VERSION ""

NS_ :

BS_:

BU_:
VAL_TABLE_ bool 1 "true" 0 "false" ;

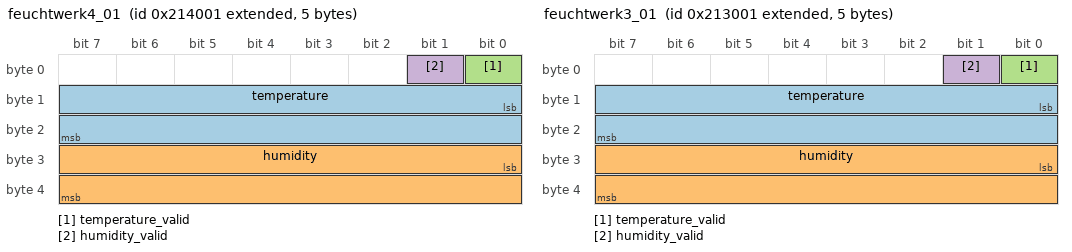
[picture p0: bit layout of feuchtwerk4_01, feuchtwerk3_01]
BO_ 2149662721 feuchtwerk4_01: 5 Vector__XXX
 SG_ temperature : 8|16@1+ (0.0025177,-40) [-40|125] "°C" Vector__XXX
 SG_ humidity : 24|16@1+ (0.00152590219,0) [0|100] "%" Vector__XXX
 SG_ temperature_valid : 0|1@1+ (1,0) [0|1] "" Vector__XXX
 SG_ humidity_valid : 1|1@1+ (1,0) [0|1] "" Vector__XXX

BO_ 2149658625 feuchtwerk3_01: 5 Vector__XXX
 SG_ temperature : 8|16@1+ (0.0025177,-40) [-40|125] "°C" Vector__XXX
 SG_ humidity : 24|16@1+ (0.00152590219,0) [0|100] "%" Vector__XXX
 SG_ temperature_valid : 0|1@1+ (1,0) [0|1] "" Vector__XXX
 SG_ humidity_valid : 1|1@1+ (1,0) [0|1] "" Vector__XXX

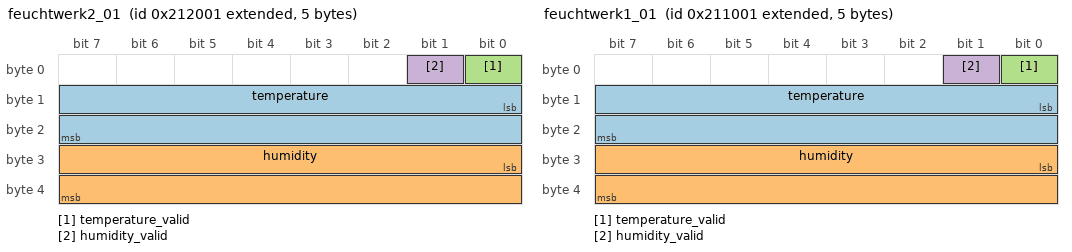
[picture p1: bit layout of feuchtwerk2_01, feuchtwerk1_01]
BO_ 2149654529 feuchtwerk2_01: 5 Vector__XXX
 SG_ temperature : 8|16@1+ (0.0025177,-40) [-40|125] "°C" Vector__XXX
 SG_ humidity : 24|16@1+ (0.00152590219,0) [0|100] "%" Vector__XXX
 SG_ temperature_valid : 0|1@1+ (1,0) [0|1] "" Vector__XXX
 SG_ humidity_valid : 1|1@1+ (1,0) [0|1] "" Vector__XXX

BO_ 2149650433 feuchtwerk1_01: 5 Vector__XXX
 SG_ temperature : 8|16@1+ (0.0025177,-40) [-40|125] "°C" Vector__XXX
 SG_ humidity : 24|16@1+ (0.00152590219,0) [0|100] "%" Vector__XXX
 SG_ temperature_valid : 0|1@1+ (1,0) [0|1] "" Vector__XXX
 SG_ humidity_valid : 1|1@1+ (1,0) [0|1] "" Vector__XXX

VAL_ 2149662721 temperature_valid 1 "true" 0 "false" ;
VAL_ 2149662721 humidity_valid 1 "true" 0 "false" ;
VAL_ 2149658625 temperature_valid 1 "true" 0 "false" ;
VAL_ 2149658625 humidity_valid 1 "true" 0 "false" ;
VAL_ 2149654529 temperature_valid 1 "true" 0 "false" ;
VAL_ 2149654529 humidity_valid 1 "true" 0 "false" ;
VAL_ 2149650433 temperature_valid 1 "true" 0 "false" ;
VAL_ 2149650433 humidity_valid 1 "true" 0 "false" ;
